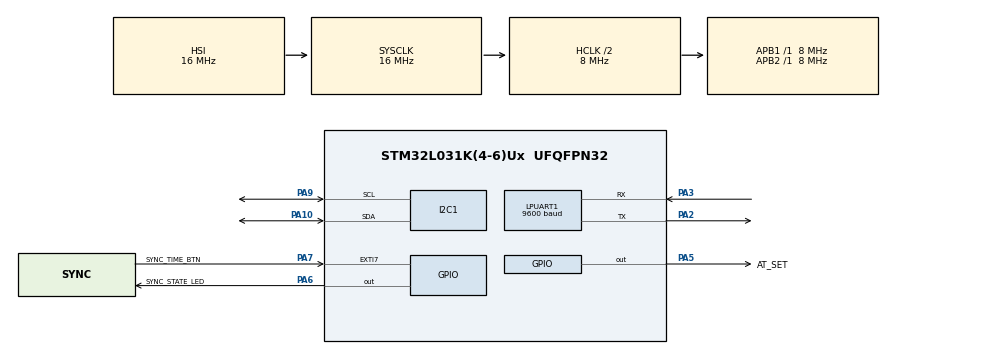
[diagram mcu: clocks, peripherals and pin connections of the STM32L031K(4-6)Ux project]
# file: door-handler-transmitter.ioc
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I2C1.Timing=0x2000090E
LPUART1.BaudRate=9600
LPUART1.WordLength=UART_WORDLENGTH_8B
Mcu.Family=STM32L0
Mcu.Name=STM32L031K(4-6)Ux
Mcu.Package=UFQFPN32
NVIC.TIM21_IRQn=true\:3\:0\:true\:false\:true\:true\:true
PA10.Mode=I2C
PA10.Signal=I2C1_SDA
PA2.Mode=Asynchronous
PA2.Signal=LPUART1_TX
PA3.Mode=Asynchronous
PA3.Signal=LPUART1_RX
PA5.GPIO_Label=AT_SET
PA5.PinState=GPIO_PIN_SET
PA5.Signal=GPIO_Output
PA6.GPIO_Label=SYNC_STATE_LED
PA6.PinState=GPIO_PIN_RESET
PA6.Signal=GPIO_Output
PA7.GPIO_Label=SYNC_TIME_BTN
PA7.Signal=GPXTI7
PA9.Mode=I2C
PA9.Signal=I2C1_SCL
PC14-OSC32_IN.Mode=LSE-External-Oscillator
PC14-OSC32_IN.Signal=RCC_OSC32_IN
PC15-OSC32_OUT.Mode=LSE-External-Oscillator
PC15-OSC32_OUT.Signal=RCC_OSC32_OUT
ProjectManager.HeapSize=0x200
ProjectManager.StackSize=0x400
ProjectManager.TargetToolchain=STM32CubeIDE
RCC.AHBCLKDivider=RCC_SYSCLK_DIV2
RCC.AHBFreq_Value=8000000
RCC.APB1Freq_Value=8000000
RCC.APB1TimFreq_Value=8000000
RCC.APB2Freq_Value=8000000
RCC.APB2TimFreq_Value=8000000
RCC.HCLKFreq_Value=8000000
RCC.HSE_VALUE=8000000
RCC.HSI16_VALUE=16000000
RCC.HSI_VALUE=16000000
RCC.MSI_VALUE=2097000
RCC.SYSCLKFreq_VALUE=16000000
RCC.SYSCLKSource=RCC_SYSCLKSOURCE_HSI
RCC.VCOOutputFreq_Value=48000000
TIM21.ClockDivision=TIM_CLOCKDIVISION_DIV1
TIM21.Period=400
TIM21.Prescaler=8 * 1024 - 1
VP_TIM21_VS_ClockSourceINT.Mode=Internal
board=custom

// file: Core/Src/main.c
/* USER CODE BEGIN Header */
/**
  ******************************************************************************
  * @file           : main.c
  * @brief          : Main program body
  ******************************************************************************
  * @attention
  *
  * Copyright (c) 2022 STMicroelectronics.
  * All rights reserved.
  *
  * This software is licensed under terms that can be found in the LICENSE file
  * in the root directory of this software component.
  * If no LICENSE file comes with this software, it is provided AS-IS.
  *
  ******************************************************************************
  */
/* USER CODE END Header */
#include "main.h"

/* USER CODE BEGIN Includes */
#include "stm32l0xx_it.h"
#include "ltr_329.h"
#include "hc12.h"
/* USER CODE END Includes */

I2C_HandleTypeDef hi2c1;

UART_HandleTypeDef hlpuart1;

TIM_HandleTypeDef htim21;

void SystemClock_Config(void);
static void MX_GPIO_Init(void);
static void MX_I2C1_Init(void);
static void MX_LPUART1_UART_Init(void);
static void MX_TIM21_Init(void);

int main(void)
{

  /* MCU Configuration--------------------------------------------------------*/

  /* Reset of all peripherals, Initializes the Flash interface and the Systick. */
  HAL_Init();

  /* Configure the system clock */
  SystemClock_Config();

  /* Initialize all configured peripherals */
  MX_GPIO_Init();
  MX_I2C1_Init();
  MX_LPUART1_UART_Init();
  MX_TIM21_Init();
  /* USER CODE BEGIN 2 */

  // Starting the measurement timer
  IT_setI2CInstance(&hi2c1, &hlpuart1);
  HC12_sleep(&hlpuart1);
  HAL_TIM_Base_Start_IT(&htim21);
  LTR_329_init(&hi2c1);
  LTR_329_writeMeasurementRate(&hi2c1, 0b00100010);

  /* USER CODE END 2 */

  /* Infinite loop */
  /* USER CODE BEGIN WHILE */
  HAL_SuspendTick();
  HAL_PWR_EnableSleepOnExit();
  HAL_PWR_EnterSLEEPMode(PWR_MAINREGULATOR_ON, PWR_SLEEPENTRY_WFI);

  while (1)
  {
    /* USER CODE END WHILE */

    /* USER CODE BEGIN 3 */
	  // With 48x flux:
	  // Light off ch1 = 95 ch0 = 54
	  // Light on ch1 = 1106 ch0 = 822

//	  HAL_Delay(500);
  }
  /* USER CODE END 3 */
}

void SystemClock_Config(void)
{
  RCC_OscInitTypeDef RCC_OscInitStruct = {0};
  RCC_ClkInitTypeDef RCC_ClkInitStruct = {0};
  RCC_PeriphCLKInitTypeDef PeriphClkInit = {0};

  /** Configure the main internal regulator output voltage
  */
  __HAL_PWR_VOLTAGESCALING_CONFIG(PWR_REGULATOR_VOLTAGE_SCALE1);
  /** Initializes the RCC Oscillators according to the specified parameters
  * in the RCC_OscInitTypeDef structure.
  */
  RCC_OscInitStruct.OscillatorType = RCC_OSCILLATORTYPE_HSI;
  RCC_OscInitStruct.HSIState = RCC_HSI_ON;
  RCC_OscInitStruct.HSICalibrationValue = RCC_HSICALIBRATION_DEFAULT;
  RCC_OscInitStruct.PLL.PLLState = RCC_PLL_NONE;
  if (HAL_RCC_OscConfig(&RCC_OscInitStruct) != HAL_OK)
  {
    Error_Handler();
  }
  /** Initializes the CPU, AHB and APB buses clocks
  */
  RCC_ClkInitStruct.ClockType = RCC_CLOCKTYPE_HCLK|RCC_CLOCKTYPE_SYSCLK
                              |RCC_CLOCKTYPE_PCLK1|RCC_CLOCKTYPE_PCLK2;
  RCC_ClkInitStruct.SYSCLKSource = RCC_SYSCLKSOURCE_HSI;
  RCC_ClkInitStruct.AHBCLKDivider = RCC_SYSCLK_DIV2;
  RCC_ClkInitStruct.APB1CLKDivider = RCC_HCLK_DIV1;
  RCC_ClkInitStruct.APB2CLKDivider = RCC_HCLK_DIV1;

  if (HAL_RCC_ClockConfig(&RCC_ClkInitStruct, FLASH_LATENCY_0) != HAL_OK)
  {
    Error_Handler();
  }
  PeriphClkInit.PeriphClockSelection = RCC_PERIPHCLK_LPUART1|RCC_PERIPHCLK_I2C1;
  PeriphClkInit.Lpuart1ClockSelection = RCC_LPUART1CLKSOURCE_PCLK1;
  PeriphClkInit.I2c1ClockSelection = RCC_I2C1CLKSOURCE_PCLK1;
  if (HAL_RCCEx_PeriphCLKConfig(&PeriphClkInit) != HAL_OK)
  {
    Error_Handler();
  }
}

static void MX_I2C1_Init(void)
{

  hi2c1.Instance = I2C1;
  hi2c1.Init.Timing = 0x2000090E;
  hi2c1.Init.OwnAddress1 = 0;
  hi2c1.Init.AddressingMode = I2C_ADDRESSINGMODE_7BIT;
  hi2c1.Init.DualAddressMode = I2C_DUALADDRESS_DISABLE;
  hi2c1.Init.OwnAddress2 = 0;
  hi2c1.Init.OwnAddress2Masks = I2C_OA2_NOMASK;
  hi2c1.Init.GeneralCallMode = I2C_GENERALCALL_DISABLE;
  hi2c1.Init.NoStretchMode = I2C_NOSTRETCH_DISABLE;
  if (HAL_I2C_Init(&hi2c1) != HAL_OK)
  {
    Error_Handler();
  }
  /** Configure Analogue filter
  */
  if (HAL_I2CEx_ConfigAnalogFilter(&hi2c1, I2C_ANALOGFILTER_ENABLE) != HAL_OK)
  {
    Error_Handler();
  }
  /** Configure Digital filter
  */
  if (HAL_I2CEx_ConfigDigitalFilter(&hi2c1, 0) != HAL_OK)
  {
    Error_Handler();
  }

}

static void MX_LPUART1_UART_Init(void)
{

  hlpuart1.Instance = LPUART1;
  hlpuart1.Init.BaudRate = 9600;
  hlpuart1.Init.WordLength = UART_WORDLENGTH_8B;
  hlpuart1.Init.StopBits = UART_STOPBITS_1;
  hlpuart1.Init.Parity = UART_PARITY_NONE;
  hlpuart1.Init.Mode = UART_MODE_TX_RX;
  hlpuart1.Init.HwFlowCtl = UART_HWCONTROL_NONE;
  hlpuart1.Init.OneBitSampling = UART_ONE_BIT_SAMPLE_DISABLE;
  hlpuart1.AdvancedInit.AdvFeatureInit = UART_ADVFEATURE_NO_INIT;
  if (HAL_UART_Init(&hlpuart1) != HAL_OK)
  {
    Error_Handler();
  }

}

static void MX_TIM21_Init(void)
{

  TIM_ClockConfigTypeDef sClockSourceConfig = {0};
  TIM_MasterConfigTypeDef sMasterConfig = {0};

  htim21.Instance = TIM21;
  htim21.Init.Prescaler = 8 * 1024 - 1;
  htim21.Init.CounterMode = TIM_COUNTERMODE_UP;
  htim21.Init.Period = 400;
  htim21.Init.ClockDivision = TIM_CLOCKDIVISION_DIV1;
  htim21.Init.AutoReloadPreload = TIM_AUTORELOAD_PRELOAD_DISABLE;
  if (HAL_TIM_Base_Init(&htim21) != HAL_OK)
  {
    Error_Handler();
  }
  sClockSourceConfig.ClockSource = TIM_CLOCKSOURCE_INTERNAL;
  if (HAL_TIM_ConfigClockSource(&htim21, &sClockSourceConfig) != HAL_OK)
  {
    Error_Handler();
  }
  sMasterConfig.MasterOutputTrigger = TIM_TRGO_RESET;
  sMasterConfig.MasterSlaveMode = TIM_MASTERSLAVEMODE_DISABLE;
  if (HAL_TIMEx_MasterConfigSynchronization(&htim21, &sMasterConfig) != HAL_OK)
  {
    Error_Handler();
  }

}

static void MX_GPIO_Init(void)
{
  GPIO_InitTypeDef GPIO_InitStruct = {0};

  /* GPIO Ports Clock Enable */
  __HAL_RCC_GPIOC_CLK_ENABLE();
  __HAL_RCC_GPIOA_CLK_ENABLE();

  /*Configure GPIO pin Output Level */
  HAL_GPIO_WritePin(AT_SET_GPIO_Port, AT_SET_Pin, GPIO_PIN_SET);

  /*Configure GPIO pin Output Level */
  HAL_GPIO_WritePin(SYNC_STATE_LED_GPIO_Port, SYNC_STATE_LED_Pin, GPIO_PIN_RESET);

  /*Configure GPIO pins : AT_SET_Pin SYNC_STATE_LED_Pin */
  GPIO_InitStruct.Pin = AT_SET_Pin|SYNC_STATE_LED_Pin;
  GPIO_InitStruct.Mode = GPIO_MODE_OUTPUT_PP;
  GPIO_InitStruct.Pull = GPIO_NOPULL;
  GPIO_InitStruct.Speed = GPIO_SPEED_FREQ_LOW;
  HAL_GPIO_Init(GPIOA, &GPIO_InitStruct);

  /*Configure GPIO pin : SYNC_TIME_BTN_Pin */
  GPIO_InitStruct.Pin = SYNC_TIME_BTN_Pin;
  GPIO_InitStruct.Mode = GPIO_MODE_IT_RISING;
  GPIO_InitStruct.Pull = GPIO_NOPULL;
  HAL_GPIO_Init(SYNC_TIME_BTN_GPIO_Port, &GPIO_InitStruct);

}

void Error_Handler(void)
{
  __disable_irq();
  while (1)
  {
  }
}
